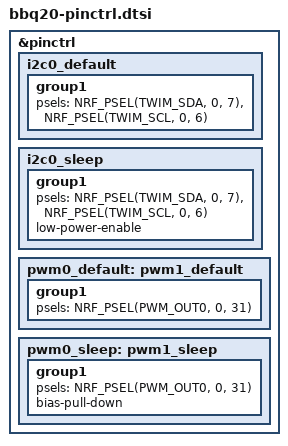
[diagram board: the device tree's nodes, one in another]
/*
 * Copyright (c) 2025 daliben123
 * SPDX-License-Identifier: MIT
 */

&pinctrl {
    i2c0_default: i2c0_default {
        group1 {
            psels = <NRF_PSEL(TWIM_SDA, 0, 7)>,
                <NRF_PSEL(TWIM_SCL, 0, 6)>;
        };
    };

    i2c0_sleep: i2c0_sleep {
        group1 {
            psels = <NRF_PSEL(TWIM_SDA, 0, 7)>,
                <NRF_PSEL(TWIM_SCL, 0, 6)>;
            low-power-enable;
        };
    };



    pwm0_default:pwm1_default{
        group1{
            psels = <NRF_PSEL(PWM_OUT0, 0, 31)>; // Backlight for Keyboard
        };
    };

    pwm0_sleep: pwm1_sleep {
        group1 {
            psels = <NRF_PSEL(PWM_OUT0, 0, 31)>;
            bias-pull-down;
        };
    };

};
